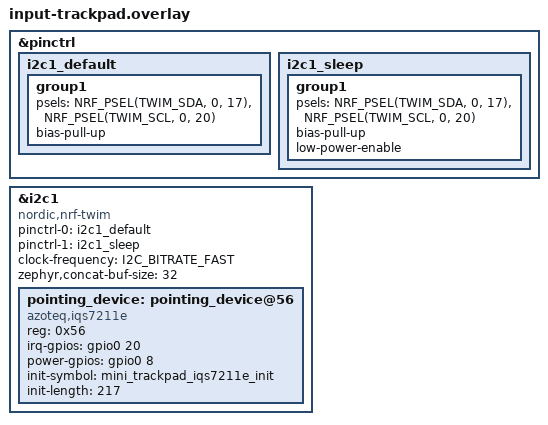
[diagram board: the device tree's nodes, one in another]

// トラックパッド用
&pinctrl {
    i2c1_default: i2c1_default {
        group1 {
            psels = <NRF_PSEL(TWIM_SDA, 0, 17)>,
                    <NRF_PSEL(TWIM_SCL, 0, 20)>;
            bias-pull-up;
        };
    };

    i2c1_sleep: i2c1_sleep {
        group1 {
            psels = <NRF_PSEL(TWIM_SDA, 0, 17)>,
                    <NRF_PSEL(TWIM_SCL, 0, 20)>;
            bias-pull-up;
            low-power-enable;
        };
    };
};

//&i2c1 {
//    status = "okay";
//    compatible = "nordic,nrf-twim";
//    pinctrl-0 = <&i2c1_default>;
//    pinctrl-1 = <&i2c1_sleep>;
//    pinctrl-names = "default", "sleep";
//    clock-frequency = <I2C_BITRATE_FAST>;
//    zephyr,concat-buf-size = <32>;
//
//    trackpad: trackpad@56 {
//        status = "okay";
//        compatible = "azoteq,iqs7211e";
//        reg = <0x56>;
//        irq-gpios = <&gpio0 21 GPIO_PULL_UP>;
//        power-gpios = <&gpio0 22 GPIO_ACTIVE_HIGH>;
//        // scroller-mode;
//        v-invert;
//    };
//};

&i2c1 {
    status = "okay";
    compatible = "nordic,nrf-twim";
    pinctrl-0 = <&i2c1_default>;
    pinctrl-1 = <&i2c1_sleep>;
    pinctrl-names = "default", "sleep";
    clock-frequency = <I2C_BITRATE_FAST>;
    zephyr,concat-buf-size = <32>;

    pointing_device: pointing_device@56 {
        status = "okay";
        compatible = "azoteq,iqs7211e";
        reg = <0x56>;
        irq-gpios = <&gpio0 20 GPIO_PULL_UP>;
        power-gpios = <&gpio0 8 (GPIO_ACTIVE_HIGH | NRF_GPIO_DRIVE_H1)>;
        init-symbol = "mini_trackpad_iqs7211e_init";
        init-length = <217>;
    };
};
